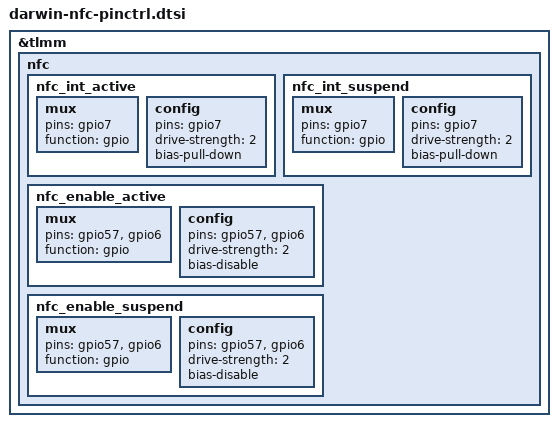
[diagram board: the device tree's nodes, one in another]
// SPDX-License-Identifier: BSD-3-Clause
/*
 * Copyright (c) 2025 Qualcomm Innovation Center, Inc. All rights reserved.
 * DARWIN project NFC pinctrl configuration (SM7750 / ST54L)
 */

&tlmm {
	nfc {
		nfc_int_active: nfc_int_active {
			mux {
				/* NFC Read Interrupt */
				pins = "gpio7";
				function = "gpio";
			};

			config {
				pins = "gpio7";
				drive-strength = <2>; /* 2 MA */
				bias-pull-down;
			};
		};

		nfc_int_suspend: nfc_int_suspend {
			mux {
				pins = "gpio7";
				function = "gpio";
			};

			config {
				pins = "gpio7";
				drive-strength = <2>; /* 2 MA */
				bias-pull-down;
			};
		};

		nfc_enable_active: nfc_enable_active {
			mux {
				/* NFC Reset and Clock Request */
				pins = "gpio57", "gpio6";
				function = "gpio";
			};

			config {
				pins = "gpio57", "gpio6";
				drive-strength = <2>; /* 2 MA */
				bias-disable;
			};
		};

		nfc_enable_suspend: nfc_enable_suspend {
			mux {
				pins = "gpio57", "gpio6";
				function = "gpio";
			};

			config {
				pins = "gpio57", "gpio6";
				drive-strength = <2>; /* 2 MA */
				bias-disable;
			};
		};
	}; //nfc
}; //tlmm
